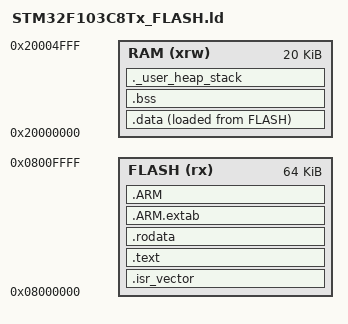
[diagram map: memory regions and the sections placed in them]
/* Linker script for STM32F103C8Tx */

/* Entry point */
ENTRY(Reset_Handler)

/* Memory regions */
MEMORY
{
  FLASH (rx)      : ORIGIN = 0x08000000, LENGTH = 64K
  RAM (xrw)       : ORIGIN = 0x20000000, LENGTH = 20K
}

/* Stack and heap sizes */
_Min_Heap_Size = 0x400;
_Min_Stack_Size = 0x600;

/* Sections */
SECTIONS
{
  /* The startup code into FLASH */
  .isr_vector :
  {
    . = ALIGN(4);
    KEEP(*(.isr_vector)) /* Startup code */
    . = ALIGN(4);
  } >FLASH

  /* The program code and other data into FLASH */
  .text :
  {
    . = ALIGN(4);
    *(.text)           /* .text sections (code) */
    *(.text*)          /* .text* sections (code) */
    *(.glue_7)         /* glue arm to thumb code */
    *(.glue_7t)        /* glue thumb to arm code */
    *(.eh_frame)
    
    KEEP (*(.init))
    KEEP (*(.fini))
    
    . = ALIGN(4);
    _etext = .;        /* define a global symbol at end of code */
  } >FLASH

  /* Constant data into FLASH */
  .rodata :
  {
    . = ALIGN(4);
    *(.rodata)         /* .rodata sections (constants, strings, etc.) */
    *(.rodata*)        /* .rodata* sections (constants, strings, etc.) */
    . = ALIGN(4);
  } >FLASH

  /* ARM sections */
  .ARM.extab :
  {
    *(.ARM.extab* .gnu.linkonce.armextab.*)
  } >FLASH

  .ARM :
  {
    __exidx_start = .;
    *(.ARM.exidx*)
    __exidx_end = .;
  } >FLASH

  /* Initialized data into RAM */
  .data :
  {
    . = ALIGN(4);
    _sdata = .;        /* create a global symbol at data start */
    *(.data)           /* .data sections */
    *(.data*)          /* .data* sections */
    
    . = ALIGN(4);
    _edata = .;        /* define a global symbol at data end */
  } >RAM AT> FLASH

  /* Uninitialized data into RAM */
  .bss :
  {
    . = ALIGN(4);
    _sbss = .;         /* create a global symbol at bss start */
    *(.bss)
    *(.bss*)
    *(COMMON)
    
    . = ALIGN(4);
    _ebss = .;         /* define a global symbol at bss end */
  } >RAM

  /* User stack section */
  ._user_heap_stack :
  {
    . = ALIGN(8);
    PROVIDE ( end = . );
    PROVIDE ( _end = . );
    . = . + _Min_Heap_Size;
    . = . + _Min_Stack_Size;
    . = ALIGN(8);
  } >RAM

  /* User stack section */
  _estack = ORIGIN(RAM) + LENGTH(RAM);

  /* Remove information from the standard libraries */
  /DISCARD/ :
  {
    libc.a ( * )
    libm.a ( * )
    libgcc.a ( * )
  }
}
